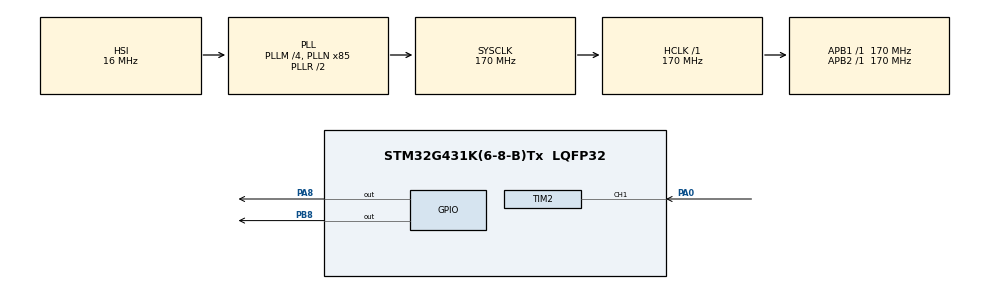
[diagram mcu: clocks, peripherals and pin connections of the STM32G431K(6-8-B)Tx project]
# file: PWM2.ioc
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Mcu.Family=STM32G4
Mcu.Name=STM32G431K(6-8-B)Tx
Mcu.Package=LQFP32
NUCLEO-G431KB.LD2=true
NUCLEO-G431KB.VCP=true
NVIC.PriorityGroup=NVIC_PRIORITYGROUP_4
NVIC.TIM2_IRQn=true\:0\:0\:false\:false\:true\:true\:true\:true
PA0.Signal=S_TIM2_CH1
PA13.GPIO_Label=T_SWDIO
PA13.Signal=SYS_JTMS-SWDIO
PA14.GPIO_Label=T_SWCLK
PA14.Signal=SYS_JTCK-SWCLK
PA2.Signal=USART2_TX
PA3.Signal=USART2_RX
PA8.Signal=GPIO_Output
PB3.GPIO_Label=T_SWO
PB3.Signal=SYS_JTDO-SWO
PB8-BOOT0.Signal=GPIO_Output
ProjectManager.HeapSize=0x200
ProjectManager.StackSize=0x400
ProjectManager.TargetToolchain=STM32CubeIDE
RCC.ADC12Freq_Value=170000000
RCC.AHBFreq_Value=170000000
RCC.APB1Freq_Value=170000000
RCC.APB1TimFreq_Value=170000000
RCC.APB2Freq_Value=170000000
RCC.APB2TimFreq_Value=170000000
RCC.CortexFreq_Value=170000000
RCC.EXTERNAL_CLOCK_VALUE=12288000
RCC.HCLKFreq_Value=170000000
RCC.HSE_VALUE=8000000
RCC.HSI48_VALUE=48000000
RCC.HSI_VALUE=16000000
RCC.LSE_VALUE=32768
RCC.PLLM=RCC_PLLM_DIV4
RCC.PLLN=85
RCC.SYSCLKFreq_VALUE=170000000
RCC.SYSCLKSource=RCC_SYSCLKSOURCE_PLLCLK
RCC.USBFreq_Value=170000000
RCC.VCOOutputFreq_Value=340000000
SH.S_TIM2_CH1.0=TIM2_CH1,PWM_Input_1
TIM2.AutoReloadPreload=TIM_AUTORELOAD_PRELOAD_ENABLE
TIM2.PeriodNoDither=4294967295
TIM2.Prescaler=0
VP_NUCLEO-G431KB_VS_BSP_COMMON.Mode=COMMON
VP_SYS_VS_DBSignals.Mode=DisableDeadBatterySignals
VP_TIM2_VS_ClockSourceINT.Mode=Internal
board=NUCLEO-G431KB

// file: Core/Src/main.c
/* USER CODE BEGIN Header */
/**
 ******************************************************************************
 * @file           : main.c
 * @brief          : Main program body
 ******************************************************************************
 * @attention
 *
 * Copyright (c) 2025 STMicroelectronics.
 * All rights reserved.
 *
 * This software is licensed under terms that can be found in the LICENSE file
 * in the root directory of this software component.
 * If no LICENSE file comes with this software, it is provided AS-IS.
 *
 ******************************************************************************
 */
/* USER CODE END Header */
#include "main.h"

COM_InitTypeDef BspCOMInit;

TIM_HandleTypeDef htim2;

void SystemClock_Config(void);
static void MX_GPIO_Init(void);
static void MX_TIM2_Init(void);

/* USER CODE BEGIN 0 */
uint32_t frequency, duty_cycle;
uint32_t capture_value;
volatile float time;
volatile float distance;
volatile float speed;

void HAL_TIM_IC_CaptureCallback(TIM_HandleTypeDef* htim) {
    if (htim->Channel == HAL_TIM_ACTIVE_CHANNEL_1) {
        capture_value = HAL_TIM_ReadCapturedValue(htim, TIM_CHANNEL_1);
        if (capture_value) {
            frequency = 170000000 / (capture_value);
            duty_cycle = 100 * HAL_TIM_ReadCapturedValue(htim, TIM_CHANNEL_2) / capture_value;
        }
    }
}

/* USER CODE END 0 */

int main(void)
{

  /* MCU Configuration--------------------------------------------------------*/

  /* Reset of all peripherals, Initializes the Flash interface and the Systick. */
  HAL_Init();

  /* Configure the system clock */
  SystemClock_Config();

  /* Initialize all configured peripherals */
  MX_GPIO_Init();
  MX_TIM2_Init();

  /* Initialize leds */
  BSP_LED_Init(LED_GREEN);

  /* Initialize COM1 port (115200, 8 bits (7-bit data + 1 stop bit), no parity */
  BspCOMInit.BaudRate   = 115200;
  BspCOMInit.WordLength = COM_WORDLENGTH_8B;
  BspCOMInit.StopBits   = COM_STOPBITS_1;
  BspCOMInit.Parity     = COM_PARITY_NONE;
  BspCOMInit.HwFlowCtl  = COM_HWCONTROL_NONE;
  if (BSP_COM_Init(COM1, &BspCOMInit) != BSP_ERROR_NONE)
  {
    Error_Handler();
  }

  /* Infinite loop */
  /* USER CODE BEGIN WHILE */
    while (1) {
        //   HAL_GPIO_TogglePin(GPIOA, GPIO_PIN_8);
        //   HAL_GPIO_TogglePin(GPIOB, GPIO_PIN_8); // dans l'autre
        //   HAL_Delay(1); // Attendre 100 ms = 0.1 seconde -> frequence de 10 normalement

        time = 1.0f / (float) frequency;       // division flottante
        distance = (1.0f / 48.0f) * 3.1415f * 0.0006f;
        speed = (distance / time) * 3600;              // en m/s

    /* USER CODE END WHILE */

    }
}

void SystemClock_Config(void)
{
  RCC_OscInitTypeDef RCC_OscInitStruct = {0};
  RCC_ClkInitTypeDef RCC_ClkInitStruct = {0};

  /** Configure the main internal regulator output voltage
  */
  HAL_PWREx_ControlVoltageScaling(PWR_REGULATOR_VOLTAGE_SCALE1_BOOST);

  /** Initializes the RCC Oscillators according to the specified parameters
  * in the RCC_OscInitTypeDef structure.
  */
  RCC_OscInitStruct.OscillatorType = RCC_OSCILLATORTYPE_HSI;
  RCC_OscInitStruct.HSIState = RCC_HSI_ON;
  RCC_OscInitStruct.HSICalibrationValue = RCC_HSICALIBRATION_DEFAULT;
  RCC_OscInitStruct.PLL.PLLState = RCC_PLL_ON;
  RCC_OscInitStruct.PLL.PLLSource = RCC_PLLSOURCE_HSI;
  RCC_OscInitStruct.PLL.PLLM = RCC_PLLM_DIV4;
  RCC_OscInitStruct.PLL.PLLN = 85;
  RCC_OscInitStruct.PLL.PLLP = RCC_PLLP_DIV2;
  RCC_OscInitStruct.PLL.PLLQ = RCC_PLLQ_DIV2;
  RCC_OscInitStruct.PLL.PLLR = RCC_PLLR_DIV2;
  if (HAL_RCC_OscConfig(&RCC_OscInitStruct) != HAL_OK)
  {
    Error_Handler();
  }

  /** Initializes the CPU, AHB and APB buses clocks
  */
  RCC_ClkInitStruct.ClockType = RCC_CLOCKTYPE_HCLK|RCC_CLOCKTYPE_SYSCLK
                              |RCC_CLOCKTYPE_PCLK1|RCC_CLOCKTYPE_PCLK2;
  RCC_ClkInitStruct.SYSCLKSource = RCC_SYSCLKSOURCE_PLLCLK;
  RCC_ClkInitStruct.AHBCLKDivider = RCC_SYSCLK_DIV1;
  RCC_ClkInitStruct.APB1CLKDivider = RCC_HCLK_DIV1;
  RCC_ClkInitStruct.APB2CLKDivider = RCC_HCLK_DIV1;

  if (HAL_RCC_ClockConfig(&RCC_ClkInitStruct, FLASH_LATENCY_4) != HAL_OK)
  {
    Error_Handler();
  }
}

static void MX_TIM2_Init(void)
{

  TIM_ClockConfigTypeDef sClockSourceConfig = {0};
  TIM_SlaveConfigTypeDef sSlaveConfig = {0};
  TIM_IC_InitTypeDef sConfigIC = {0};
  TIM_MasterConfigTypeDef sMasterConfig = {0};

  htim2.Instance = TIM2;
  htim2.Init.Prescaler = 0;
  htim2.Init.CounterMode = TIM_COUNTERMODE_UP;
  htim2.Init.Period = 4294967295;
  htim2.Init.ClockDivision = TIM_CLOCKDIVISION_DIV1;
  htim2.Init.AutoReloadPreload = TIM_AUTORELOAD_PRELOAD_ENABLE;
  if (HAL_TIM_Base_Init(&htim2) != HAL_OK)
  {
    Error_Handler();
  }
  sClockSourceConfig.ClockSource = TIM_CLOCKSOURCE_INTERNAL;
  if (HAL_TIM_ConfigClockSource(&htim2, &sClockSourceConfig) != HAL_OK)
  {
    Error_Handler();
  }
  if (HAL_TIM_IC_Init(&htim2) != HAL_OK)
  {
    Error_Handler();
  }
  sSlaveConfig.SlaveMode = TIM_SLAVEMODE_RESET;
  sSlaveConfig.InputTrigger = TIM_TS_TI1FP1;
  sSlaveConfig.TriggerPolarity = TIM_INPUTCHANNELPOLARITY_RISING;
  sSlaveConfig.TriggerPrescaler = TIM_ICPSC_DIV1;
  sSlaveConfig.TriggerFilter = 0;
  if (HAL_TIM_SlaveConfigSynchro(&htim2, &sSlaveConfig) != HAL_OK)
  {
    Error_Handler();
  }
  sConfigIC.ICPolarity = TIM_INPUTCHANNELPOLARITY_RISING;
  sConfigIC.ICSelection = TIM_ICSELECTION_DIRECTTI;
  sConfigIC.ICPrescaler = TIM_ICPSC_DIV1;
  sConfigIC.ICFilter = 0;
  if (HAL_TIM_IC_ConfigChannel(&htim2, &sConfigIC, TIM_CHANNEL_1) != HAL_OK)
  {
    Error_Handler();
  }
  sConfigIC.ICPolarity = TIM_INPUTCHANNELPOLARITY_FALLING;
  sConfigIC.ICSelection = TIM_ICSELECTION_INDIRECTTI;
  if (HAL_TIM_IC_ConfigChannel(&htim2, &sConfigIC, TIM_CHANNEL_2) != HAL_OK)
  {
    Error_Handler();
  }
  sMasterConfig.MasterOutputTrigger = TIM_TRGO_RESET;
  sMasterConfig.MasterSlaveMode = TIM_MASTERSLAVEMODE_DISABLE;
  if (HAL_TIMEx_MasterConfigSynchronization(&htim2, &sMasterConfig) != HAL_OK)
  {
    Error_Handler();
  }
  /* USER CODE BEGIN TIM2_Init 2 */
    HAL_TIM_IC_Start_IT(&htim2, TIM_CHANNEL_1);
    HAL_TIM_IC_Start_IT(&htim2, TIM_CHANNEL_2);

  /* USER CODE END TIM2_Init 2 */

}

static void MX_GPIO_Init(void)
{
  GPIO_InitTypeDef GPIO_InitStruct = {0};

  /* GPIO Ports Clock Enable */
  __HAL_RCC_GPIOA_CLK_ENABLE();
  __HAL_RCC_GPIOB_CLK_ENABLE();

  /*Configure GPIO pin Output Level */
  HAL_GPIO_WritePin(GPIOA, GPIO_PIN_8, GPIO_PIN_RESET);

  /*Configure GPIO pin Output Level */
  HAL_GPIO_WritePin(GPIOB, GPIO_PIN_8, GPIO_PIN_RESET);

  /*Configure GPIO pin : PA8 */
  GPIO_InitStruct.Pin = GPIO_PIN_8;
  GPIO_InitStruct.Mode = GPIO_MODE_OUTPUT_PP;
  GPIO_InitStruct.Pull = GPIO_NOPULL;
  GPIO_InitStruct.Speed = GPIO_SPEED_FREQ_LOW;
  HAL_GPIO_Init(GPIOA, &GPIO_InitStruct);

  /*Configure GPIO pin : PB8 */
  GPIO_InitStruct.Pin = GPIO_PIN_8;
  GPIO_InitStruct.Mode = GPIO_MODE_OUTPUT_PP;
  GPIO_InitStruct.Pull = GPIO_NOPULL;
  GPIO_InitStruct.Speed = GPIO_SPEED_FREQ_LOW;
  HAL_GPIO_Init(GPIOB, &GPIO_InitStruct);

}

/* USER CODE BEGIN Header */
/**
 ******************************************************************************
 * @file           : main.c
 * @brief          : Main program body
 ******************************************************************************
 * @attention
 *
 * Copyright (c) 2025 STMicroelectronics.
 * All rights reserved.
 *
 * This software is licensed under terms that can be found in the LICENSE file
 * in the root directory of this software component.
 * If no LICENSE file comes with this software, it is provided AS-IS.
 *
 ******************************************************************************
 */
/* USER CODE END Header */

void Error_Handler(void)
{
    __disable_irq();
    while (1) {
    }
}
